# SAM9X75D1M device description
Architecture: ARM926EJ-S; Family: SAM9; Series: SAM9X7
Registers are 32-bit, read-write, reset 0x0 unless marked. A register's access mark holds for its fields unless they carry their own. Offsets are from the block's base; [hi:lo] are bit positions; {n}, {i} and the like mark numbered series; 'fields as' and 'values as' point back to an identical list.

## OTPC — OTP Memory Controller
Instances: OTPC 0xEFF00000
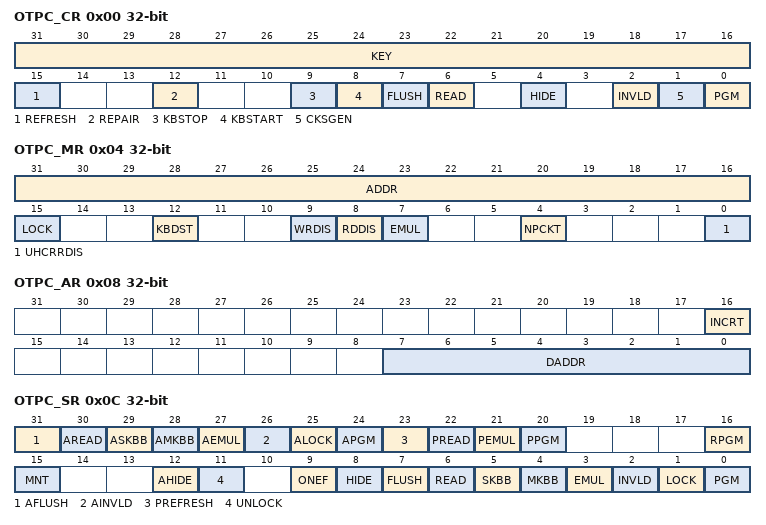
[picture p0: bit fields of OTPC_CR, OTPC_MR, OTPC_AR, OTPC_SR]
0x00 OTPC_CR wo reset not defined — Control Register
  [31:16] KEY — Programming Key
  [15] REFRESH — Refresh the Area
    0=No effect; 1=Starts a refresh of the area
  [12] REPAIR — Live Repair
    0=No effect; 1=Starts the OTP live repair
  [9] KBSTOP — Key Bus Transfer Stop
    0=No effect; 1=Stops an on-going transfer on the Master Key bus
  [8] KBSTART — Key Bus Transfer Start
    0=No effect; 1=Starts a transfer through the Master Key bus
  [7] FLUSH — Flush Temporary Registers
    0=No effect; 1=Starts a flush of the temporary registers used to store the payload of the packet
  [6] READ — Read Packet
    0=No effect; 1=Starts a read sequence of the selected packet
  [4] HIDE — Hide Packet
    0=No effect; 1=The selected packet is not readable anymore until the next reset
  [2] INVLD — Invalidate Packet
    0=No effect; 1=Invalidates the selected packet
  [1] CKSGEN — Generate Checksum
    0=No effect; 1=Generates and programs the selected packet checksum. This action also locks the packet.
  [0] PGM — Program Packet
    0=No effect; 1=The selected packet is written
0x04 OTPC_MR — Mode Register
  [31:16] ADDR — Address
  [15] LOCK
    0=The OTPC_MR register is unlocked; write access changes its value; 1=The OTPC_MR register is locked; write access does not change its value
  [12] KBDST — Key Bus Destination
    0=TDES (The TDES is the destination of the key transfer.); 1=AES (The AES is the destination of the key transfer.)
  [9] WRDIS — Write Disable
    0=The write capability of the OTPC_DR register is enabled; 1=The write capability of the OTPC_DR register is disabled
  [8] RDDIS — Read Disable
    0=The read capability of the OTPC_HR and OTPC_DR registers are enabled; 1=The read capability of the OTPC_HR and OTPC_DR registers are disabled. In case of read, the returned value is 0.
  [7] EMUL — Emulation Enable
    0=The Emulation mode of the User area is disabled, all accesses are computed in the OTP memory; 1=The Emulation mode of the User area is enabled, all accesses are computed in the Emulation memory
  [4] NPCKT — New Packet
    0=Updates the packet defined at the ADDR address; 1=Creates a new packet
  [0] UHCRRDIS — User Hardware Configuration Register Read Disable
    0=The User Hardware Configuration register can be read through the User Interface; 1=The User Hardware Configuration register cannot be read through the User Interface
0x08 OTPC_AR — Address Register
  [16] INCRT — Increment Type
    0=AFTER_READ (Increment DADDR after a read of OTPC_DR.); 1=AFTER_WRITE (Increment DADDR after a write of OTPC_DR.)
  [7:0] DADDR — Data Address
0x0C OTPC_SR ro — Status Register
  [31] AFLUSH — Engineering Flush On-Going
    0=The temporary registers are not flushed; 1=The temporary registers are being flushed
  [30] AREAD — Engineering Read On-Going
    0=No engineering packet read is on-going; 1=An engineering packet read is running
  [29] ASKBB — Engineering Slave Key Bus Busy
    0=The Slave Key bus is not busy; 1=The Slave Key bus is busy
  [28] AMKBB — Engineering Master Key Bus Busy
    0=The Master Key bus is not busy; 1=The Master Key bus is busy
  [27] AEMUL — Engineering Emulation Enabled
    0=The Engineering area Emulation mode is disabled; 1=The Engineering area Emulation mode is enabled
  [26] AINVLD — Engineering Invalidation On-Going
    0=No engineering packet invalidation is on-going; 1=An engineering packet invalidation is running
  [25] ALOCK — Engineering Lock On-Going
    0=No engineering packet locking is on-going; 1=An engineering packet locking is running
  [24] APGM — Engineering Programming On-Going
    0=No engineering packet programming is on-going; 1=An engineering packet programming is running
  [23] PREFRESH — Patch Refresh On-Going
    0=The patches are no being refreshed
  [22] PREAD — Patch Read On-Going
    0=No patch read is on-going; 1=A patch read is on-going
  [21] PEMUL — Patch Emulation Enabled
    0=The Patch area Emulation mode is disabled; 1=The Patch area Emulation mode is enabled
  [20] PPGM — Patch Programming On-Going
    0=No patch programming is on-going; 1=A patch programming is running
  [16] RPGM — ROM Programming On-Going
    0=No ROM programming is on-going; 1=A ROM programming is running
  [15] MNT — Maintenance On-Going
    0=The OTP live repair is not running; 1=The OTP live repair is running, OTP maintenance is running
  [12] AHIDE — Hiding On-Going
    0=No engineering packet hiding is on-going; 1=An engineering packet hiding is on-going
  [11] UNLOCK — OTP Registers Unlocked
    0=The OTPC_ODCxR and OTPC_OPCxR registers are locked; 1=The OTPC_ODCxR and OTPC_OPCxR registers are unlocked
  [9] ONEF — One Found
    0=No bit at '1' found during the last packet read; 1=At least one '1' has been found during the last packet read
  [8] HIDE — Hiding On-Going
    0=No packet hiding is on-going; 1=A packet hiding is on-going
  [7] FLUSH — Flush On-Going
    values as AFLUSH
  [6] READ — Read On-Going
    0=No packet read is on-going; 1=A packet read is running
  [5] SKBB — Slave Key Bus Busy
    0=The Slave Key bus is not busy; 1=The Slave Key bus is busy
  [4] MKBB — Master Key Bus Busy
    values as AMKBB
  [3] EMUL — Emulation Enabled
    0=The User area Emulation mode is disabled; 1=The User area Emulation mode is enabled
  [2] INVLD — Invalidation On-Going
    0=No packet invalidation is on-going; 1=A packet invalidation is running
  [1] LOCK — Lock On-Going
    0=No packet locking is on-going; 1=A packet locking is running
  [0] PGM — Programming On-Going
    0=No packet programming is on-going; 1=A packet programming is running
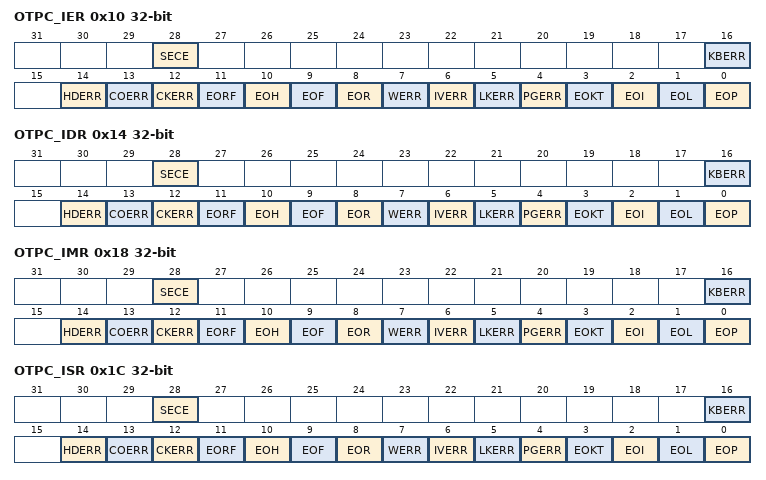
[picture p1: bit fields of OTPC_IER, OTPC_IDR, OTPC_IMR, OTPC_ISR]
0x10 OTPC_IER wo reset not defined (atomic set of OTPC_IMR) — Interrupt Enable Register
  [28] SECE — Security and/or Safety Event Interrupt Enable
  [16] KBERR — Key Bus Error Interrupt Enable
  [14] HDERR — Hide Error Interrupt Enable
  [13] COERR — Corruption Error Interrupt Enable
  [12] CKERR — Checksum Check Error Interrupt Enable
  [11] EORF — End Of Refresh Interrupt Enable
  [10] EOH — End Of Hide Interrupt Enable
  [9] EOF — End Of Flush Interrupt Enable
  [8] EOR — End Of Read Interrupt Enable
  [7] WERR — Write Error Interrupt Enable
  [6] IVERR — Invalidation Error Interrupt Enable
  [5] LKERR — Locking Error Interrupt Enable
  [4] PGERR — Programming Error Interrupt Enable
  [3] EOKT — End Of Key Transfer Interrupt Enable
  [2] EOI — End Of Invalidation Interrupt Enable
  [1] EOL — End Of Locking Interrupt Enable
  [0] EOP — End Of Programming Interrupt Enable
0x14 OTPC_IDR wo reset not defined (atomic clear of OTPC_IMR) — Interrupt Disable Register
  [28] SECE — Security and/or Safety Event Interrupt Disable
  [16] KBERR — Key Bus Error Interrupt Disable
  [14] HDERR — Hide Error Interrupt Disable
  [13] COERR — Corruption Error Interrupt Disable
  [12] CKERR — Checksum Check Error Interrupt Disable
  [11] EORF — End Of Refresh Interrupt Disable
  [10] EOH — End Of Hide Interrupt Disable
  [9] EOF — End Of Flush Interrupt Disable
  [8] EOR — End Of Read Interrupt Disable
  [7] WERR — Write Error Interrupt Disable
  [6] IVERR — Invalidation Error Interrupt Disable
  [5] LKERR — Locking Error Interrupt Disable
  [4] PGERR — Programming Error Interrupt Disable
  [3] EOKT — End Of Key Transfer Interrupt Disable
  [2] EOI — End Of Invalidation Interrupt Disable
  [1] EOL — End Of Locking Interrupt Disable
  [0] EOP — End Of Programming Interrupt Disable
0x18 OTPC_IMR ro — Interrupt Mask Register
  [28] SECE — Security and/or Safety Event Interrupt Mask
  [16] KBERR — Key Bus Error Interrupt Mask
  [14] HDERR — Hide Error Interrupt Mask
  [13] COERR — Corruption Error Interrupt Mask
  [12] CKERR — Checksum Check Error Interrupt Mask
  [11] EORF — End Of Refresh Interrupt Mask
  [10] EOH — End Of Hide Interrupt Mask
  [9] EOF — End Of Flush Interrupt Mask
  [8] EOR — End Of Read Interrupt Mask
  [7] WERR — Write Error Interrupt Mask
  [6] IVERR — Invalidation Error Interrupt Mask
  [5] LKERR — Locking Error Interrupt Mask
  [4] PGERR — Programming Error Interrupt Mask
  [3] EOKT — End Of Key Transfer Interrupt Mask
  [2] EOI — End Of Invalidation Interrupt Mask
  [1] EOL — End Of Locking Interrupt Mask
  [0] EOP — End Of Programming Interrupt Mask
0x1C OTPC_ISR ro — Interrupt Status Register
  [28] SECE — Security and/or Safety Event (cleared on read)
    0=No security or safety event occurred since the last read of OTPC_ISR; 1=One or more safety or security event occurred since the last read of OTPC_ISR. For details on the event, refer to OTPC_WPSR.
  [16] KBERR — Key Bus Error (cleared on read)
    0=No error happened on the Key bus since the last read of OTPC_ISR; 1=An error happened on the Key bus since the last read of OTPC_ISR
  [14] HDERR — Hide Error (cleared on read)
    0=No hiding error occurred since the last read of OTPC_ISR; 1=A hiding error occurred since the last read of OTPC_ISR
  [13] COERR — Corruption Error (cleared on read)
    0=No corruption occurred during the last start-up since the last read of OTPC_ISR; 1=A corruption occurred since the last read of OTPC_ISR
  [12] CKERR — Checksum Check Error (cleared on read)
    0=No checksum check failure occurred during last reading sequence since the last read of OTPC_ISR; 1=A checksum check failure occurred since the last read of OTPC_ISR
  [11] EORF — End Of Refresh (cleared on read)
    0=No refresh sequence completion since the last read of OTPC_ISR; 1=At least one refresh sequence completion since the last read of OTPC_ISR
  [10] EOH — End Of Hide (cleared on read)
    0=No hiding sequence completion since the last read of OTPC_ISR; 1=At least one hiding sequence completion since the last read of OTPC_ISR
  [9] EOF — End Of Flush (cleared on read)
    0=No flush of the temporary registers since the last read of OTPC_ISR; 1=At least one flush hof the temporary registers has been completed since the last read of OTPC_ISR
  [8] EOR — End Of Read (cleared on read)
    0=No reading sequence completion since the last read of OTPC_ISR; 1=At least one reading sequence completion since the last read of OTPC_ISR
  [7] WERR — Write Error (cleared on read)
    0=No write error occurred since the last read of OTPC_ISR; 1=A write error occurred since the last read of OTPC_ISR
  [6] IVERR — Invalidation Error (cleared on read)
    0=No invalidation failure occurred during last invalidation sequence since the last read of OTPC_ISR; 1=A invalidation failure occurred since the last read of OTPC_ISR
  [5] LKERR — Locking Error (cleared on read)
    0=No locking failure occurred during last locking sequence since the last read of OTPC_ISR; 1=A locking failure occurred since the last read of OTPC_ISR
  [4] PGERR — Programming Error (cleared on read)
    0=No programming failure occurred during last programming sequence since the last read of OTPC_ISR; 1=A programming failure occurred since the last read of OTPC_ISR
  [3] EOKT — End Of Key Transfer (cleared on read)
    0=No key transfer completion since the last read of OTPC_ISR; 1=At least one key transfer has been completed on the Master Key bus since the last read of OTPC_ISR
  [2] EOI — End Of Invalidation (cleared on read)
    0=No invalidation sequence completion since the last read of OTPC_ISR; 1=At least one invalidation sequence completion since the last read of OTPC_ISR
  [1] EOL — End Of Locking (cleared on read)
    0=No locking sequence completion since the last read of OTPC_ISR; 1=At least one locking sequence completion since the last read of OTPC_ISR
  [0] EOP — End Of Programming (cleared on read)
    0=No programming sequence completion since the last read of OTPC_ISR; 1=At least one programming sequence completion since the last read of OTPC_ISR
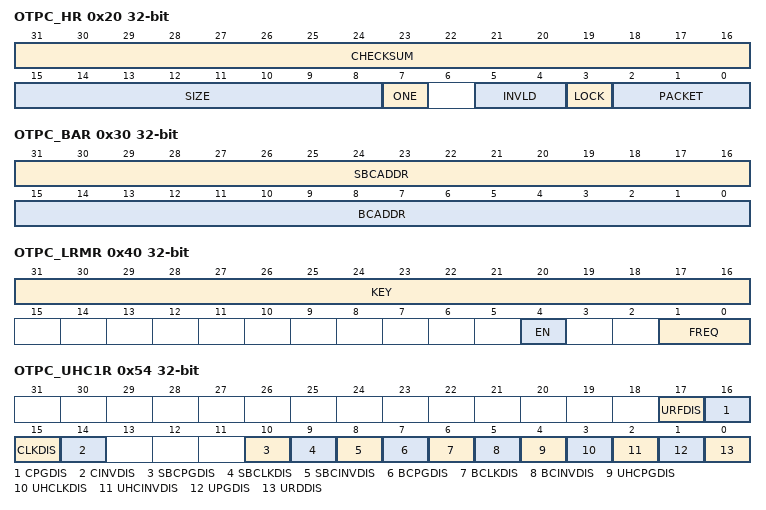
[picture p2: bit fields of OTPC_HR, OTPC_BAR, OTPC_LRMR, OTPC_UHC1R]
0x20 OTPC_HR — Header Register
  [31:16] CHECKSUM — Packet Checksum
  [15:8] SIZE — Packet Size
  [7] ONE
  [5:4] INVLD — Invalid Status
  [3] LOCK — Lock Status
    0=The packet is not locked; 1=The packet is locked
  [2:0] PACKET — Packet Type
    1=REGULAR (Regular packet accessible through the User Interface); 2=KEY (Key packet accessible only through the Key Buses); 3=BOOT_CONFIGURATION (Boot Configuration packet); 4=SECURE_BOOT_CONFIGURATION (Secure Boot Configuration packet); 5=HARDWARE_CONFIGURATION (Hardware Configuration packet); 6=CUSTOM (Custom packet)
0x24 OTPC_DR (atomic clear of OTPC_SR) — Data Register
  [31:0] DATA — Packet Data
0x30 OTPC_BAR ro — Boot Addresses Register
  [31:16] SBCADDR — Secure Boot Configuration Address
  [15:0] BCADDR — Boot Configuration Address
0x34 OTPC_CAR ro — Custom Address Register
  [15:0] CADDR — Custom Address
0x40 OTPC_LRMR — Live Repair Mode Register
  [31:16] KEY — Programming Key
  [4] EN — Automatic Live Repair Enable
    0=The automatic start of OTP live repair is disabled; 1=The automatic start of OTP live repair is enabled
  [1:0] FREQ — Automatic Live Repair Frequency
    0=ONE_DAY (The live repair is started every day); 1=FOUR_DAYS (The live repair is started every 4 days); 2=EIGHT_DAYS (The live repair is started every 8 days); 3=SIXTEEN_DAYS (The live repair is started every 16 days)
0x50 OTPC_UHC0R ro — User Hardware Configuration 0 Register
  [7:0] JTAGDIS — JTAG Disable
    0=The JTAG is enabled
0x54 OTPC_UHC1R ro — User Hardware Configuration 1 Register
  [17] URFDIS — User Refresh Disable
    0=The OTPC_CR.REFRESH bit is fully functional; 1=The OTPC_CR.REFRESH bit is only functional in Emulation mode
  [16] CPGDIS — Custom Packet Program Disable
    0=The programming of Custom Special Packet is allowed; 1=The programming of Custom Special Packet is forbidden
  [15] CLKDIS — Custom Packet Lock Disable
    0=The generation of the checksum (lock) of the Custom Special Packet is allowed; 1=The generation of the checksum (lock) of the Custom Special Packet is forbidden
  [14] CINVDIS — Custom Packet Invalidation Disable
    0=The invalidation of the Custom Special Packet is allowed; 1=The invalidation of the Custom Special Packet is forbidden
  [10] SBCPGDIS — Secure Boot Configuration Packet Program Disable
    0=The programming of Secure Boot Configuration Special Packet is allowed; 1=The programming of Secure Boot Configuration Special Packet is forbidden
  [9] SBCLKDIS — Secure Boot Configuration Packet Lock Disable
    0=The generation of the checksum (lock) of the Secure Boot Configuration Special Packet is allowed; 1=The generation of the checksum (lock) of the Secure Boot Configuration Special Packet is forbidden
  [8] SBCINVDIS — Secure Boot Configuration Packet Invalidation Disable
    0=The invalidation of the Secure Boot Configuration Special Packet is allowed; 1=The invalidation of the Secure Boot Configuration Special Packet is forbidden
  [7] BCPGDIS — Boot Configuration Packet Program Disable
    0=The programming of Boot Configuration Special Packet is allowed; 1=The programming of Boot Configuration Special Packet is forbidden
  [6] BCLKDIS — Boot Configuration Packet Lock Disable
    0=The generation of the checksum (lock) of the Boot Configuration Special Packet is allowed; 1=The generation of the checksum (lock) of the Boot Configuration Special Packet is forbidden
  [5] BCINVDIS — Boot Configuration Packet Invalidation Disable
    0=The invalidation of the Boot Configuration Special Packet is allowed; 1=The invalidation of the Boot Configuration Special Packet is forbidden
  [4] UHCPGDIS — User Hardware Configuration Packet Program Disable
    0=The programming of User Hardware Configuration Special Packet is allowed; 1=The programming of User Hardware Configuration Special Packet is forbidden
  [3] UHCLKDIS — User Hardware Configuration Packet Lock Disable
    0=The generation of the checksum (lock) of the User Hardware Configuration Special Packet is allowed; 1=The generation of the checksum (lock) of the User Hardware Configuration Special Packet is forbidden
  [2] UHCINVDIS — User Hardware Configuration Packet Invalidation Disable
    0=The invalidation of the User Hardware Configuration Special Packet is allowed; 1=The invalidation of the User Hardware Configuration Special Packet is forbidden
  [1] UPGDIS — User programming Disable
    0=The OTPC_CR.PGM bit is fully functional; 1=The OTPC_CR.PGM bit is not functional
  [0] URDDIS — User Read Disable
    0=The OTPC_CR.READ bit is fully functional; 1=The OTPC_CR.READ bit is not functional
{0x60+4i} OTPC_UID{i}R ro reset not defined (i=0..3) — Product UID {i} Register
  [31:0] UID — Unique Product ID
0x70 OTPC_HCSR — Hardware Configuration Selection Register
  [3:0] HCSEL — Hardware Configuration Selection
0x74 OTPC_HCDR ro (atomic clear of OTPC_HCSR) — Hardware Configuration Data Register
  [31:0] HCFG — Hardware Configuration Value
0x80 OTPC_HS0R ro reset not defined — Hardware Security 0 Register
  [31:0] SCFG — Security Configuration Value
0x84 OTPC_HS1R ro reset not defined — Hardware Security 1 Register
  [31:0] SCFG — Security Configuration Value
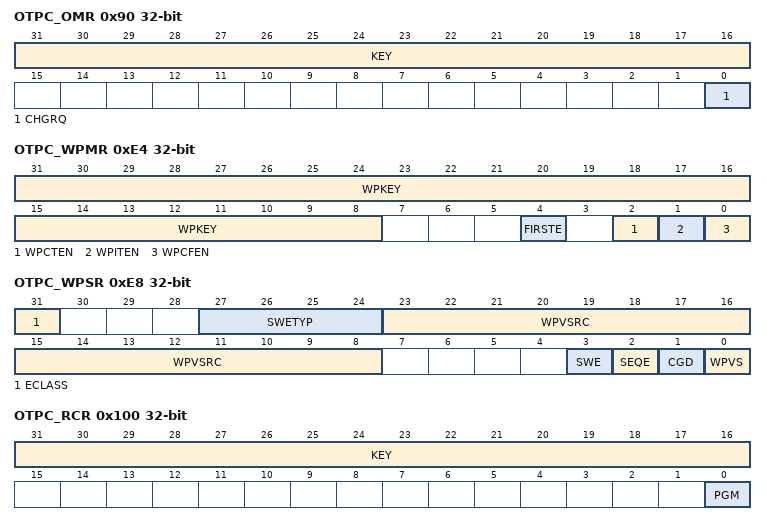
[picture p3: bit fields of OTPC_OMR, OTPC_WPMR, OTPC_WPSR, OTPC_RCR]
0x90 OTPC_OMR — OTP Mode Register
  [31:16] KEY
  [0] CHGRQ — Change Request
    0=Cancels the request to change the OTPC_ODCxR and OTPC_OPCxR registers; 1=Requests a change of the OTPC_ODCxR and OTPC_OPCxR registers
{0xA0+4i} OTPC_ODC{i}R reset not defined (i=0..3) — OTP DAP Configuration {i} Register
  [31:0] DAPCFG — DAP Configuration
{0xB0+4i} OTPC_OPC{i}R reset not defined (i=0..3) — OTP PMC Configuration {i} Register
  [31:0] PMCCFG — PMC Configuration
0xE4 OTPC_WPMR — Write Protection Mode Register
  [31:8] WPKEY — Write Protection Key
    0x4F5450=PASSWD (Writing any other value in this field aborts the write operation. Always reads as 0.)
  [4] FIRSTE — First Error Report Enable
    0=The last write protection violation source is reported in OTPC_WPSR.WPVSRC and the last software control error type is reported in OTPC_WPSR.SWETYP; The OTPC_ISR.SECE flag is set at the first error occurrence within a series; 1=Only the first write protection violation source is reported in OTPC_WPSR.WPVSRC and only the first software control error type is reported in OTPC_WPSR.SWETYP. The OTPC_ISR.SECE flag is set at the first error occurrence within a series.
  [2] WPCTEN — Write Protection Control Enable
    0=Disables the write protection of the control if WPKEY matches to 0x4F5450 (OTP in ASCII); 1=Enables the write protection of the control if WPKEY matches to 0x4F5450 (OTP in ASCII)
  [1] WPITEN — Write Protection Interrupt Enable
    0=Disables the write protection of the interruption configuration if WPKEY matches to 0x4F5450 (OTP in ASCII); 1=Enables the write protection of the interruption configuration if WPKEY matches to 0x4F5450 (OTP in ASCII)
  [0] WPCFEN — Write Protection Configuration Enable
    0=Disables the write protection of the configuration if WPKEY matches to 0x4F5450 (OTP in ASCII); 1=Enables the write protection of the configuration if WPKEY matches to 0x4F5450 (OTP in ASCII)
0xE8 OTPC_WPSR ro — Write Protection Status Register
  [31] ECLASS — Software Error Class
    0=WARNING (An abnormal access that does not have any impact.); 1=ERROR (An abnormal access that may have an impact.)
  [27:24] SWETYP — Software Error Type
    0=READ_WO (A write-only register has been read (warning).); 1=WRITE_RO (A write access has been performed on a read-only register (warning).); 2=CONF_CHG (A change has been made into the configuration (error).); 3=KEY_ERROR (A write has been computed in OTPC_CR, OTPC_ACR, OTPC_RCR, OTPC_PCR, OTPC_OMR or OTPC_WPMR register with a wrong value in the related KEY field (error).)
  [23:8] WPVSRC — Write Protection Violation Source
  [3] SWE — Software Control Error (cleared on read)
    0=No software error has occurred since the last read of OTPC_WPSR; 1=A software error has occurred since the last read of OTPC_WPSR. The field SWETYP details the type of software error encountered.
  [2] SEQE — Internal Sequencer Error (cleared on read)
    0=No peripheral internal sequencer error has occurred since the last read of OTPC_WPSR; 1=A peripheral internal sequencer error has occurred since the last read of OTPC_WPSR. This flag can be set under abnormal operating conditions.
  [1] CGD — Clock Glitch Detected (cleared on read)
    0=No clock glitch has occurred since the last read of OTPC_WPSR; 1=A clock glitch has occurred since the last read of OTPC_WPSR. This flag can be set under abnormal operating conditions.
  [0] WPVS — Write Protection Violation Status (cleared on read)
    0=No write protection violation has occurred since the last read of OTPC_WPSR; 1=A write protection violation has occurred since the last read of OTPC_WPSR. If this violation is an unauthorized attempt to write a protected register, the associated violation is reported into WPVSRC.
0x100 OTPC_RCR wo reset not defined — ROM Control Register
  [31:16] KEY — Programming Key
  [0] PGM — Program
    0=No effect; 1=The OTPC ROM Data Register is written at the address specified in the OTPC ROM Address Register
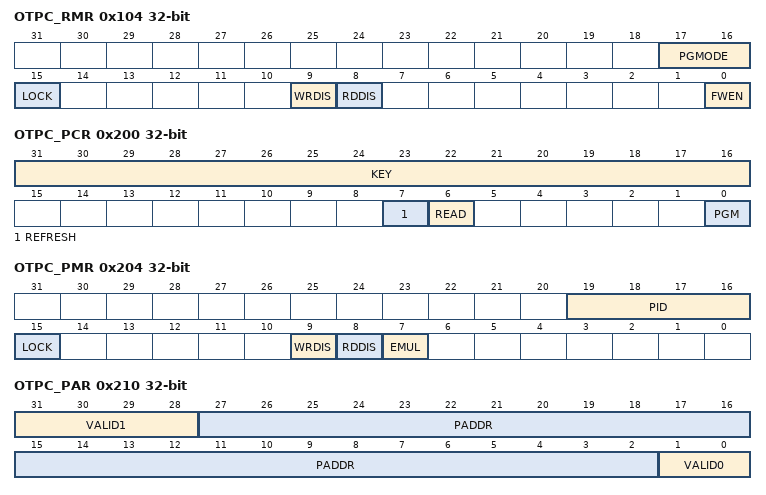
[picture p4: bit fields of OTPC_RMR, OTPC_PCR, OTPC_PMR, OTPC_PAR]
0x104 OTPC_RMR — ROM Mode Register
  [17:16] PGMODE — Programming Mode
    0=ROM_NO_PGM (ROM Code programming is disabled); 1=ROM_SBUS_PGM (ROM Code programming through System Bus Slave Interface); 2=ROM_UI_ADDR_CONST_PGM (ROM Code programming through User Interface); 3=ROM_UI_ADDR_INCR_PGM (ROM Code programming through User Interface with OTPC_RAR incremented after each programming.)
  [15] LOCK
    0=The OTPC_RMR register is not locked, any write access can change its content; 1=The OTPC_RMR register is locked, write access does not change its value
  [9] WRDIS — Write Disable
    0=The write capability of the OTPC_RCR, OTPC_RMR, OTPC_RAR and OTPC_RDR registers is enabled; 1=The write capability of the OTPC_RCR, OTPC_RMR, OTPC_RAR and OTPC_RDR registers is disabled. Only WRDIS and LOCK bits remain writeable (unless LOCK is set).
  [8] RDDIS — Read Disable
    0=The read capability of the OTPC_RCR, OTPC_RMR, OTPC_RAR and OTPC_RDR registers is enabled; 1=The read capability of the OTPC_RCR, OTPC_RMR, OTPC_RAR and OTPC_RDR registers is disabled. In case of read, the returned value is 0.
  [0] FWEN — Firewall Enable
    0=The firewall is disabled; 1=The firewall is enabled, all read and write accesses are denied and an error is returned on the system bus
0x110 OTPC_RAR — ROM Address Register
  [31:2] RADDR — ROM Address
0x114 OTPC_RDR — ROM Data Register
  [31:0] RDATA — ROM Data
0x200 OTPC_PCR wo reset not defined — Patch Control Register
  [31:16] KEY — Programming Key
  [7] REFRESH — Refresh Patches
    0=No effect; 1=Read all patches from OTP and activate them
  [6] READ — Read Patch
    0=No effect; 1=The patch specified by PID field of OTPC_PMR is read
  [0] PGM — Program
    0=No effect; 1=The OTPC Patch Address and OTPC Patch Data registers are written
0x204 OTPC_PMR — Patch Mode Register
  [19:16] PID — Patch ID
  [15] LOCK
    0=The OTPC_PMR register is not locked, any write access can change its content; 1=The OTPC_PMR register is locked, write access does not change its value
  [9] WRDIS — Write Disable
    0=The write capability of the OTPC_PCR, OTPC_PMR, OTPC_PAR and OTPC_PDR registers is enabled; 1=The write capability of the OTPC_PCR, OTPC_PMR, OTPC_PAR and OTPC_PDR registers is disabled. Only WRDIS and LOCK bits remain writeable (unless LOCK is set).
  [8] RDDIS — Read Disable
    0=The read capability of the OTPC_PCR, OTPC_PMR, OTPC_PSR, OTPC_PAR and OTPC_PDR registers is enabled; 1=The read capability of the OTPC_PCR, OTPC_PMR, OTPC_PSR, OTPC_PAR and OTPC_PDR registers is disabled. In case of read, the returned value is 0.
  [7] EMUL — Emulation Mode
    0=Disables the Emulation mode; 1=Enables the Emulation mode
0x208 OTPC_PSR — Patch Software Register
  [31:0] SOFT — Software Value
0x210 OTPC_PAR — Patch Address Register
  [31:28] VALID1 — Patch Validity
  [27:2] PADDR — Patch Address
  [1:0] VALID0 — Patch Validity
0x214 OTPC_PDR (atomic clear of OTPC_PSR) — Patch Data Register
  [31:0] PDATA — Patch Data
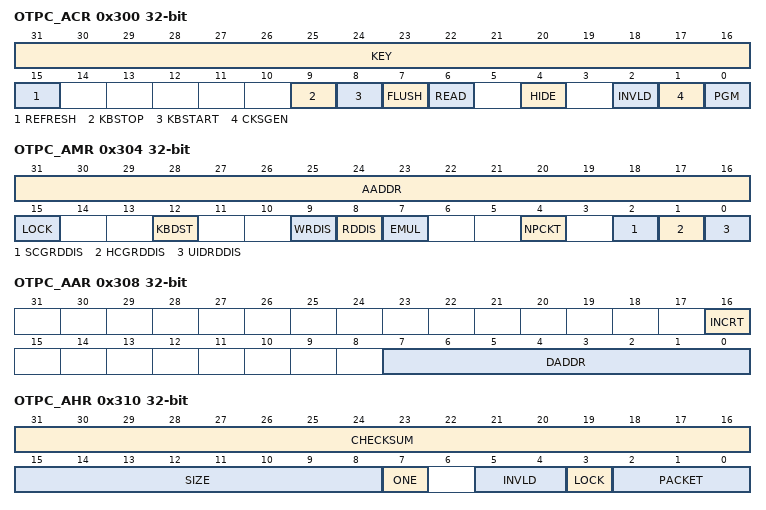
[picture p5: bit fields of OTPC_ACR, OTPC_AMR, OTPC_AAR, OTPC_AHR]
0x300 OTPC_ACR wo reset not defined — A Control Register
  [31:16] KEY — Programming Key
  [15] REFRESH — Refresh the Area
    0=No effect; 1=Starts a refresh of the area in the Emulation mode
  [9] KBSTOP — Key Bus Transfer Stop
    values as OTPC_CR.KBSTOP
  [8] KBSTART — Key Bus Transfer Start
    0=No effect; 1=Starts a transfer through the Master Key bus
  [7] FLUSH — Flush Temporary Registers
    values as OTPC_CR.FLUSH
  [6] READ — Read Packet
    0=No effect; 1=Starts a read sequence of the selected packet
  [4] HIDE — Hide Packet
    0=No effect; 1=The selected engineering packet is not readable anymore until the next reset
  [2] INVLD — Invalidate Packet
    0=No effect; 1=Invalidates the selected engineering packet
  [1] CKSGEN — Generate Checksum
    0=No effect; 1=Generates and programs the selected engineering packet checksum
  [0] PGM — Program Packet
    0=No effect; 1=The selected engineering packet is written
0x304 OTPC_AMR — A Mode Register
  [31:16] AADDR — Address
  [15] LOCK
    0=The OTPC_AMR register is not locked; any write access can change its content; 1=The OTPC_AMR register is locked; write access does not change its value
  [12] KBDST — Key Bus Destination
    values as OTPC_MR.KBDST
  [9] WRDIS — Write Disable
    0=The write capability of the OTPC_ACR, OTPC_AMR, OTPC_AAR, OTPC_AHR and OTPC_ADR registers is enabled; 1=The write capability of the OTPC_ACR, OTPC_AMR, OTPC_AAR, OTPC_AHR and OTPC_ADR registers is disabled. Only WRDIS and LOCK bits remain writeable (unless LOCK is set).
  [8] RDDIS — Read Disable
    0=The read capability of the OTPC_ACR, OTPC_AMR, OTPC_AAR, OTPC_AHR and OTPC_ADR registers is enabled; 1=The read capability of the OTPC_ACR, OTPC_AMR, OTPC_AAR, OTPC_AHR and OTPC_ADR registers is disabled. In case of read, the returned value is 0.
  [7] EMUL — Emulation Mode
    0=Disables the Emulation mode; 1=Enables the Emulation mode
  [4] NPCKT — New Packet
    values as OTPC_MR.NPCKT
  [2] SCGRDDIS — Security Configuration Register Read Disable
    0=The OTPC_SCR register is readable; 1=The OTPC_SCR register is not readable, value read is 0
  [1] HCGRDDIS — Hardware Configuration Register Read Disable
    0=The OTPC_HCR register is readable; 1=The OTPC_HCR register is not readable, value read is 0
  [0] UIDRDDIS — UID Register Read Disable
    0=The OTPC_UIDR register is readable; 1=The OTPC_UIDR register is not readable, value read is 0
0x308 OTPC_AAR — A Address Register
  [16] INCRT — Increment Type
    0=AFTER_READ (Increment DADDR after a read of OTPC_ADR.); 1=AFTER_WRITE (Increment DADDR after a write of OTPC_ADR.)
  [7:0] DADDR — Data Address
0x310 OTPC_AHR — A Header Register
  [31:16] CHECKSUM — Packet Checksum
  [15:8] SIZE — Packet Size
  [7] ONE
  [5:4] INVLD — Invalid Status
  [3] LOCK — Lock Status
    0=The packet is not locked; 1=The packet is locked
  [2:0] PACKET — Packet Type
    1=REGULAR (Regular packet accessible through the User Interface.); 2=KEY (Key packet accessible only through the Key buses.); 4=PRODUCT_UID (Product UID packet.); 5=HARDWARE_CONFIGURATION (Hardware Configuration packet.); 6=SECURITY_CONFIGURATION (Security Configuration packet.)
0x314 OTPC_ADR — A Data Register
  [31:0] ADATA — Engineering Packet Data
